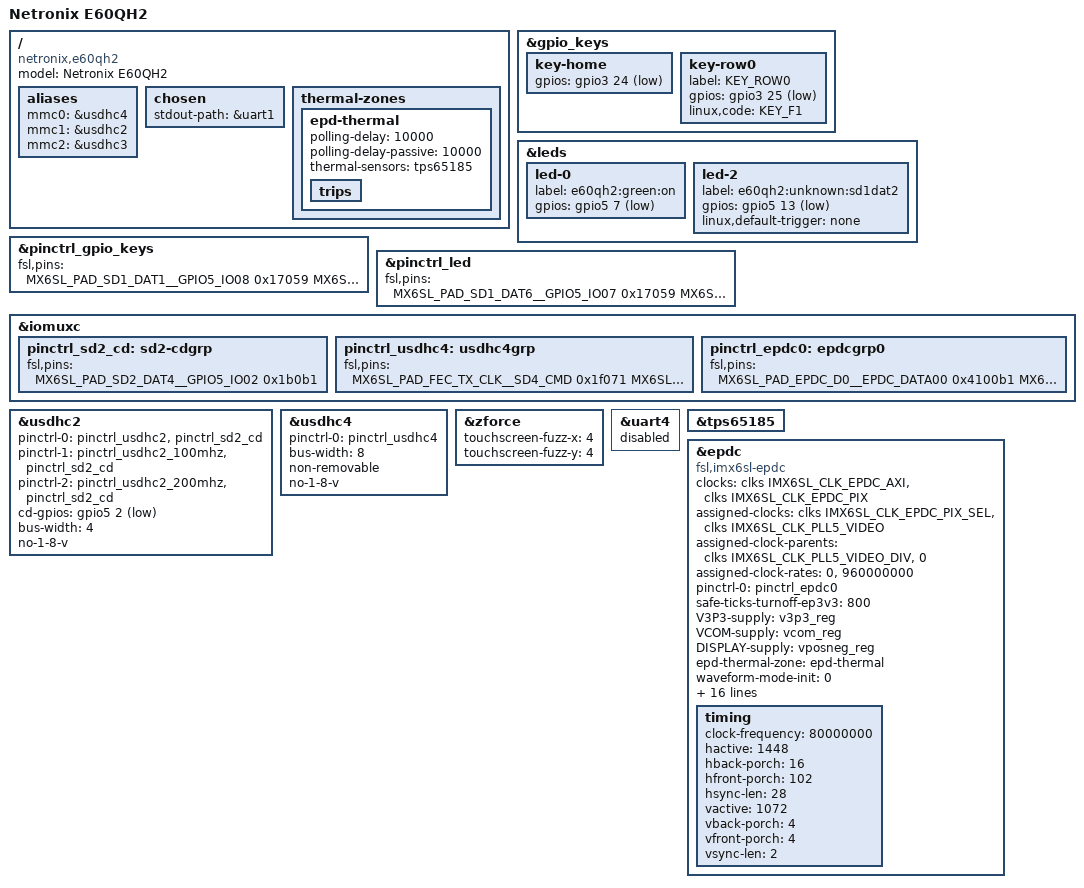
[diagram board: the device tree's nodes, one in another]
// SPDX-License-Identifier: GPL-2.0
/*
 * Netronix KB-E60QH2 ebook reader (Slovak Telekom variant)
 * Mainboard: 37NB-E60QH0+4A1, hwconfig PCB = E60QH0
 *
 * Near-twin of the Tolino Shine 2 HD (E60QF2). Differences measured on the
 * live device (stock kernel GPIO table + IOMUXC dump, see docs/hwmap_raw/):
 *  - system storage is an 8-bit eMMC on uSDHC4 (FEC pads), not an internal uSD
 *  - uSDHC2 is the removable microSD slot, card detect on SD2_DAT4 (gpio5 2)
 *  - home button on KEY_COL0 (gpio3 24)
 *  - "on" LED on SD1_DAT6 (gpio5 7)
 */

#include "imx6sl-tolino-shine2hd.dts"

/ {
	model = "Netronix E60QH2";
	compatible = "netronix,e60qh2", "kobo,tolino-shine2hd", "fsl,imx6sl";

	aliases {
		mmc0 = &usdhc4;	/* eMMC */
		mmc1 = &usdhc2;	/* microSD slot */
		mmc2 = &usdhc3;	/* WiFi */
		/delete-property/ mmc3;
	};

	chosen {
		stdout-path = &uart1;
	};
};

&gpio_keys {
	key-home {
		gpios = <&gpio3 24 GPIO_ACTIVE_LOW>;
	};

	/* Shine 2 HD home pad; muxed as GPIO here too, purpose unknown */
	key-row0 {
		label = "KEY_ROW0";
		gpios = <&gpio3 25 GPIO_ACTIVE_LOW>;
		linux,code = <KEY_F1>;
	};
};

&leds {
	led-0 {
		label = "e60qh2:green:on";
		gpios = <&gpio5 7 GPIO_ACTIVE_LOW>;
	};

	/* Shine 2 HD LED position, kept for testing */
	led-2 {
		label = "e60qh2:unknown:sd1dat2";
		gpios = <&gpio5 13 GPIO_ACTIVE_LOW>;
		linux,default-trigger = "none";
	};
};

&pinctrl_gpio_keys {
	fsl,pins = <
		MX6SL_PAD_SD1_DAT1__GPIO5_IO08  0x17059	/* power */
		MX6SL_PAD_SD1_DAT4__GPIO5_IO12  0x17059	/* hall sensor */
		MX6SL_PAD_KEY_COL0__GPIO3_IO24  0x17059	/* home */
		MX6SL_PAD_KEY_COL1__GPIO3_IO26  0x17059
		MX6SL_PAD_KEY_ROW0__GPIO3_IO25  0x17059
	>;
};

&pinctrl_led {
	fsl,pins = <
		MX6SL_PAD_SD1_DAT6__GPIO5_IO07    0x17059
		MX6SL_PAD_SD1_DAT2__GPIO5_IO13    0x17059
		MX6SL_PAD_EPDC_SDCE2__GPIO1_IO29  0x17059
	>;
};

&iomuxc {
	pinctrl_sd2_cd: sd2-cdgrp {
		fsl,pins = <
			MX6SL_PAD_SD2_DAT4__GPIO5_IO02	0x1b0b1
		>;
	};

	/* values as programmed by the stock kernel */
	pinctrl_usdhc4: usdhc4grp {
		fsl,pins = <
			MX6SL_PAD_FEC_TX_CLK__SD4_CMD	0x1f071
			MX6SL_PAD_FEC_MDIO__SD4_CLK	0x1f071
			MX6SL_PAD_FEC_RX_ER__SD4_DATA0	0x1f071
			MX6SL_PAD_FEC_CRS_DV__SD4_DATA1	0x1f071
			MX6SL_PAD_FEC_RXD1__SD4_DATA2	0x1f071
			MX6SL_PAD_FEC_TXD0__SD4_DATA3	0x1f071
			MX6SL_PAD_FEC_MDC__SD4_DATA4	0x1f071
			MX6SL_PAD_FEC_RXD0__SD4_DATA5	0x1f071
			MX6SL_PAD_FEC_TX_EN__SD4_DATA6	0x1f071
			MX6SL_PAD_FEC_TXD1__SD4_DATA7	0x1f071
		>;
	};
};

&usdhc2 {
	/delete-property/ non-removable;
	pinctrl-0 = <&pinctrl_usdhc2 &pinctrl_sd2_cd>;
	pinctrl-1 = <&pinctrl_usdhc2_100mhz &pinctrl_sd2_cd>;
	pinctrl-2 = <&pinctrl_usdhc2_200mhz &pinctrl_sd2_cd>;
	cd-gpios = <&gpio5 2 GPIO_ACTIVE_LOW>;
	bus-width = <4>;
	no-1-8-v;
};

&usdhc4 {
	pinctrl-names = "default";
	pinctrl-0 = <&pinctrl_usdhc4>;
	bus-width = <8>;
	non-removable;
	no-1-8-v;
	status = "okay";
};

/*
 * The zForce jitters by 1-3 units while a finger rests; input-core hysteresis
 * keeps taps from turning into tiny drags.
 */
&zforce {
	touchscreen-fuzz-x = <4>;
	touchscreen-fuzz-y = <4>;
};

/* TP198 on the Shine 2 HD; not verified on this board, keep pads untouched */
&uart4 {
	status = "disabled";
};

/*
 * E-Ink panel (EPDC). Timing as programmed by the stock kernel
 * (mode "PENG060D", extracted from the stock 3.0.35 Image); identical to
 * the values in Andreas Kemnade's Tolino Shine 2 HD EPDC tree.
 */
/ {
	thermal-zones {
		epd-thermal {
			polling-delay = <10000>;
			polling-delay-passive = <10000>;
			thermal-sensors = <&tps65185>;

			trips {
			};
		};
	};
};

&tps65185 {
	#thermal-sensor-cells = <0>;
};

&epdc {
	compatible = "fsl,imx6sl-epdc", "fsl,imx-epdc";
	clocks = <&clks IMX6SL_CLK_EPDC_AXI>, <&clks IMX6SL_CLK_EPDC_PIX>;
	clock-names = "epdc_axi", "epdc_pix";
	/*
	 * Stock clocks epdc_pix from PLL5 at 79.999999 MHz during updates
	 * (docs/hwmap_raw/epdc_compare/). The default parent (pll3_pfd1, 540 MHz)
	 * only gives 77.14 MHz; 960 MHz / 12 = 80 MHz exactly.
	 */
	assigned-clocks = <&clks IMX6SL_CLK_EPDC_PIX_SEL>,
			  <&clks IMX6SL_CLK_PLL5_VIDEO>;
	assigned-clock-parents = <&clks IMX6SL_CLK_PLL5_VIDEO_DIV>, <0>;
	assigned-clock-rates = <0>, <960000000>;
	pinctrl-names = "default";
	pinctrl-0 = <&pinctrl_epdc0>;
	safe-ticks-turnoff-ep3v3 = <800>;	/* stock: "EP3V3 OFF ticks=800" */
	V3P3-supply = <&v3p3_reg>;
	VCOM-supply = <&vcom_reg>;
	DISPLAY-supply = <&vposneg_reg>;
	epd-thermal-zone = "epd-thermal";

	/*
	 * Mode table of the ED060KG1 waveform (320_R057_AF2701), decoded from
	 * frame counts / drive patterns (linux/tools/wfmodes.py):
	 * 0 INIT, 1 DU, 2 GC16, 3-5 GL16/GLR16/GLD16 (identical data), 6 A2, 7 DU4.
	 * gc4 is used by the hardware auto-select for 4-level content.
	 */
	waveform-mode-init = <0>;
	waveform-mode-du = <1>;
	waveform-mode-gc16 = <2>;
	waveform-mode-gc4 = <3>;
	waveform-mode-gl16 = <3>;
	waveform-mode-a2 = <6>;
	waveform-mode-du4 = <7>;

	vscan-holdoff = <4>;
	sdoed-width = <10>;
	sdoed-delay = <20>;
	sdoez-width = <10>;
	sdoez-delay = <20>;
	gdclk-hp-offs = <562>;
	gdsp-offs = <662>;
	gdoe-offs = <0>;
	gdclk-offs = <225>;
	num-ce = <3>;
	status = "okay";

	timing {
		clock-frequency = <80000000>;
		hactive = <1448>;
		hback-porch = <16>;
		hfront-porch = <102>;
		hsync-len = <28>;
		vactive = <1072>;
		vback-porch = <4>;
		vfront-porch = <4>;
		vsync-len = <2>;
	};
};

&iomuxc {
	/* 0x400000 = LVE (1.8 V-capable pad, low-voltage mode) */
	pinctrl_epdc0: epdcgrp0 {
		fsl,pins = <
			MX6SL_PAD_EPDC_D0__EPDC_DATA00		0x4100b1
			MX6SL_PAD_EPDC_D1__EPDC_DATA01		0x4100b1
			MX6SL_PAD_EPDC_D2__EPDC_DATA02		0x4100b1
			MX6SL_PAD_EPDC_D3__EPDC_DATA03		0x4100b1
			MX6SL_PAD_EPDC_D4__EPDC_DATA04		0x4100b1
			MX6SL_PAD_EPDC_D5__EPDC_DATA05		0x4100b1
			MX6SL_PAD_EPDC_D6__EPDC_DATA06		0x4100b1
			MX6SL_PAD_EPDC_D7__EPDC_DATA07		0x4100b1
			MX6SL_PAD_EPDC_D8__EPDC_DATA08		0x4100b1
			MX6SL_PAD_EPDC_D9__EPDC_DATA09		0x4100b1
			MX6SL_PAD_EPDC_D10__EPDC_DATA10		0x4100b1
			MX6SL_PAD_EPDC_D11__EPDC_DATA11		0x4100b1
			MX6SL_PAD_EPDC_D12__EPDC_DATA12		0x4100b1
			MX6SL_PAD_EPDC_D13__EPDC_DATA13		0x4100b1
			MX6SL_PAD_EPDC_D14__EPDC_DATA14		0x4100b1
			MX6SL_PAD_EPDC_D15__EPDC_DATA15		0x4100b1
			MX6SL_PAD_EPDC_SDCLK__EPDC_SDCLK_P	0x4100b1
			MX6SL_PAD_EPDC_SDLE__EPDC_SDLE		0x4100b1
			MX6SL_PAD_EPDC_SDOE__EPDC_SDOE		0x4100b1
			MX6SL_PAD_EPDC_SDSHR__EPDC_SDSHR	0x4100b1
			MX6SL_PAD_EPDC_SDCE0__EPDC_SDCE0	0x4100b1
			MX6SL_PAD_EPDC_GDCLK__EPDC_GDCLK	0x4100b1
			MX6SL_PAD_EPDC_GDOE__EPDC_GDOE		0x4100b1
			MX6SL_PAD_EPDC_GDRL__EPDC_GDRL		0x4100b1
			MX6SL_PAD_EPDC_GDSP__EPDC_GDSP		0x4100b1
		>;
	};
};
